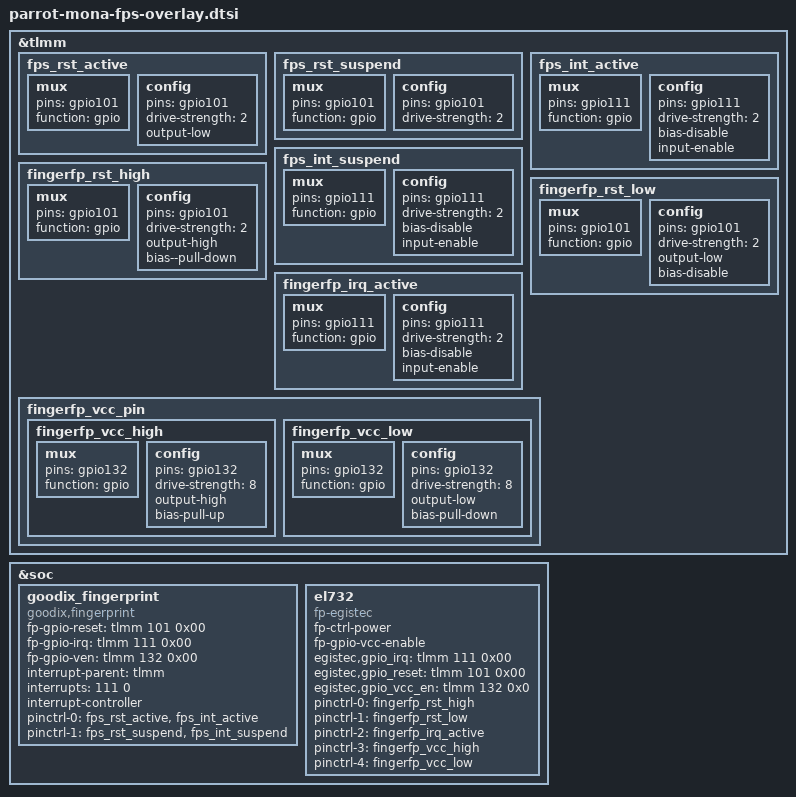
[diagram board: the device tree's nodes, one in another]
&tlmm {
	fps_rst_active: fps_rst_active {
                /* active state */
                mux {
                        pins = "gpio101";
                        function = "gpio";
                };

                config {
                        pins = "gpio101";
                        drive-strength = <2>; /* 2 MA */
                        output-low;
                };
        };

        fps_rst_suspend: fps_rst_suspend {
                /* sleep state */
                mux {
                        pins = "gpio101";
                        function = "gpio";
                };

                config {
                        pins = "gpio101";
                        drive-strength = <2>; /* 2 MA */
                };
        };

        fps_int_active: fps_int_active {
                /* active state */
                mux {
                        pins = "gpio111";
                        function = "gpio";
                };

                config {
                        pins = "gpio111";
                        drive-strength = <2>; /* 2 MA */
                        bias-disable;
                        input-enable;
                };
        };

        fps_int_suspend: fps_int_suspend {
                /* sleep state */
                mux {
                        pins = "gpio111";
                        function = "gpio";
                };

                config {
                        pins = "gpio111";
                        drive-strength = <2>; /* 2 MA */
                        bias-disable;
                        input-enable;
                };
        };

	fingerfp_rst_high: fingerfp_rst_high {
		mux {
			pins = "gpio101";
			function = "gpio";
		};

		config {
			pins = "gpio101";
			drive-strength = <2>;
			output-high;
			bias--pull-down;
		};
	};

	fingerfp_rst_low: fingerfp_rst_low {
		mux {
			pins = "gpio101";
			function = "gpio";
		};
		config {
			pins = "gpio101";
			drive-strength = <2>;
			output-low;
			bias-disable;
		};
	};

	fingerfp_irq_active: fingerfp_irq_active {
		mux {
			pins = "gpio111";
			function = "gpio";
		};
		config {
			pins = "gpio111";
			drive-strength = <2>;
			bias-disable;
			input-enable;
		};
	};
	fingerfp_vcc_pin: fingerfp_vcc_pin {
		fingerfp_vcc_high: fingerfp_vcc_high {
			mux {
				pins = "gpio132";
				function = "gpio";
			};

			config {
				pins = "gpio132";
				drive-strength = <8>;
				output-high;
				bias-pull-up;
			};
		};

		fingerfp_vcc_low: fingerfp_vcc_low {
			mux {
				pins = "gpio132";
				function = "gpio";
			};

			config {
				pins = "gpio132";
				drive-strength = <8>;
				output-low;
				bias-pull-down;
			};
		};
	};
};

&soc {
	goodix_fingerprint {
		compatible = "goodix,fingerprint";
		status = "ok";
		fp-gpio-reset = <&tlmm 101 0x00>;
		fp-gpio-irq = <&tlmm 111 0x00>;
		fp-gpio-ven = <&tlmm 132 0x00>;
		interrupt-parent = <&tlmm>;
		interrupts = <111 0>;
		interrupt-controller;
		pinctrl-names = "default", "suspend";
		pinctrl-0 = <&fps_rst_active &fps_int_active>;
		pinctrl-1 = <&fps_rst_suspend &fps_int_suspend>;
	};

	el732: el732 {
		status = "ok";
		compatible = "fp-egistec";
		fp-ctrl-power;
		fp-gpio-vcc-enable;
		egistec,gpio_irq = <&tlmm 111 0x00>;
		egistec,gpio_reset = <&tlmm 101 0x00>;
		egistec,gpio_vcc_en = <&tlmm 132 0x0>;
		pinctrl-names = "egis_rst_high", "egis_rst_low", "egis_irq_active","egis_vcc_high", "egis_vcc_low";
		pinctrl-0 = <&fingerfp_rst_high>;
		pinctrl-1 = <&fingerfp_rst_low>;
		pinctrl-2 = <&fingerfp_irq_active>;
		pinctrl-3 = <&fingerfp_vcc_high>;
		pinctrl-4 = <&fingerfp_vcc_low>;
	};
};
